# SC32F10T_10G register map
File version: 1.0
CPU: CM0+ r0p1, little endian, MPU, no FPU, 4 interrupt priority bits
Registers are 32-bit, read-write, reset 0x0 unless marked. A register's access mark holds for its fields unless they carry their own. Offsets are from the block's base; [hi:lo] are bit positions; 'fields as' and 'values as' point back to an identical list.

## UART0
Base 0x40020020
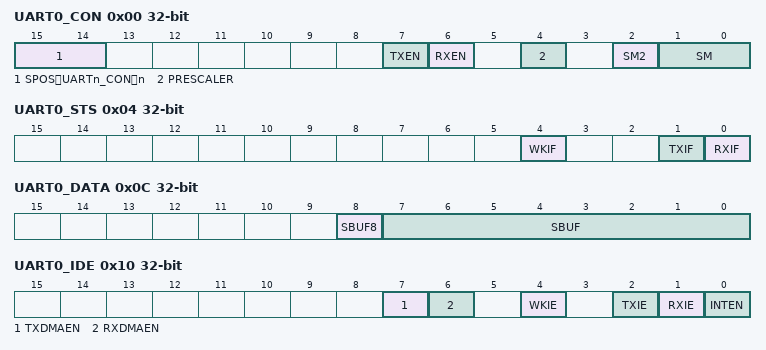
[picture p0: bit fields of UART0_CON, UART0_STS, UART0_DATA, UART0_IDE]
0x00 UART0_CON — UART控制寄存器
  [15:14] SPOS（UARTn_CON，n — 此bit位，仅在UARTn_CON，n=2的情况下有效：UART2信号口映射控制位@UART2_CON信号SPOS值RX2TX2SPOS[1:0]=00PB0PA15SPOS[1:0]=01PA11PA10
  [7] TXEN — UART发送允许控制位0：不允许发送数据，TXD信号不再影响所在管脚的状态。此时若用户程序限制发送功能，仅用到了接收，那么与TX脚复用的其它功能将不受影响1：允许发送数据，TXD所在管脚切换为TXD信号口模式
  [6] RXEN — UART接收允许控制位0：不允许接收数据1：允许接收数据
  [4] PRESCALER — 波特率倍率设置位该位在UART的不同模式下有不同定义：当SM0~1 = 01（UART模式1）或SM0~1 = 11（UART模式3）：0: 串行端口在系统时钟的1分频下运行1: 串行端口在系统时钟的16分频下运行当SM0~1 = 00（UART模式0）波特率倍率设置位：0：串行端口在系统时钟的12分频下运行1：串行端口在系统时钟的4分频下运行
  [2] SM2 — RB8置位中断允许位该位仅在模式3有效0：每收到一个完整的数据帧就置位RI产生中断请求；1：收到一个完整的数据帧时，只有当RB8=1时才会置位RI产生中断请求
  [1:0] SM — UART通信模式控制位00：模式0，8位半双工同步通信模式，在RX引脚上收发串行数据。TX 引脚用作发送移位时钟。每帧收发8位，低位先接收或发送。在该模式下使能RXEN位，UART将发出一个完整一帧的时钟，并且将RXIF置1；01：模式1，10位全双工异步通信，由1个起始位，8个数据位和1个停止位组成，通信波特率可变；10：保留11：模式3，11位全双工异步通信，由1个起始位，8个数据位，一个可编
0x04 UART0_STS — UART标志位寄存器
  [4] WKIF — UART唤醒标志位UART从STOP模式唤醒后，该位由硬件置1，如果此时WKIE = 1，将产生中断。该位由软件写1清0。
  [1] TXIF — 发送中断标志位数据发送完成该位由硬件置1，如果此时TXIE = 1，将产生中断。该位由软件写1清0。注意：在DMA模式下，DMA写入发送缓存后，该位由DMA模块清0，此时用户无需通过软件清0。
  [0] RXIF — 接收中断标志位数据接收完成该位由硬件置1，如果此时RXIE = 1，将产生中断。该位由软件写1清0。注意：在DMA模式下，DMA读取接收缓存后，该位由DMA模块清0，此时用户无需通过软件清0。
0x08 UART0_BAUD — UART波特率寄存器
  [15:0] BAUD — UART波特率配置位写入BAUD[15:0]后，UART的波特率将按照以下公式配置：BaudRate=fUART / BAUD[15:0]其中fUART为UART时钟源经预分频之后的最终频率，见PRESCALER位说明。
0x0C UART0_DATA — UART数据寄存器
  [8] SBUF8 — UART的发送/接收数据的第9位该位仅在模式3有效。
  [7:0] SBUF — UART数据缓存读操作：将返回接收锁存器中的内容写操作：SBUF的数据将送至发送移位寄存器，并启动发送流程
0x10 UART0_IDE — 通信口DMA控制寄存器
  [7] TXDMAEN — DMA发送通道使能位0：禁用DMA发送功能1：使能DMA发送功能该位使能后，TXIF置起可触发DMA通道发送请求注意：UART0和UART1可产生DMA请求UART2和UART3不能产生DMA请求
  [6] RXDMAEN — DMA接收通道使能位0：禁用DMA接收功能1：使能DMA接收功能该位使能后，RXIF置起可触发DMA通道接收请求注意：UART0和UART1可产生DMA请求UART2和UART3不能产生DMA请求
  [4] WKIE — UART唤醒中断使能位0：WKIF置起时，不允许产生中断1：WKIF置起时，产生中断
  [2] TXIE — UART发送中断使能位0：TXIF置起时，不允许产生中断1：TXIF置起时，产生中断
  [1] RXIE — UART接收中断使能位0：RXIF置起时，不允许产生中断1：RXIF置起时，产生中断
  [0] INTEN — 中断请求 CPU的使能控制位0：禁止中断请求1：使能中断请求

## UART1
Base 0x40020080
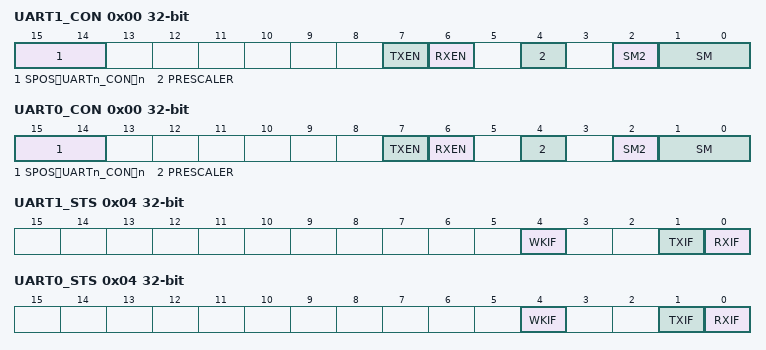
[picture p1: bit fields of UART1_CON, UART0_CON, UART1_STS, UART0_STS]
0x00 UART1_CON — UART控制寄存器
  [15:14] SPOS（UARTn_CON，n — 此bit位，仅在UARTn_CON，n=2的情况下有效：UART2信号口映射控制位@UART2_CON信号SPOS值RX2TX2SPOS[1:0]=00PB0PA15SPOS[1:0]=01PA11PA10
  [7] TXEN — UART发送允许控制位0：不允许发送数据，TXD信号不再影响所在管脚的状态。此时若用户程序限制发送功能，仅用到了接收，那么与TX脚复用的其它功能将不受影响1：允许发送数据，TXD所在管脚切换为TXD信号口模式
  [6] RXEN — UART接收允许控制位0：不允许接收数据1：允许接收数据
  [4] PRESCALER — 波特率倍率设置位该位在UART的不同模式下有不同定义：当SM0~1 = 01（UART模式1）或SM0~1 = 11（UART模式3）：0: 串行端口在系统时钟的1分频下运行1: 串行端口在系统时钟的16分频下运行当SM0~1 = 00（UART模式0）波特率倍率设置位：0：串行端口在系统时钟的12分频下运行1：串行端口在系统时钟的4分频下运行
  [2] SM2 — RB8置位中断允许位该位仅在模式3有效0：每收到一个完整的数据帧就置位RI产生中断请求；1：收到一个完整的数据帧时，只有当RB8=1时才会置位RI产生中断请求
  [1:0] SM — UART通信模式控制位00：模式0，8位半双工同步通信模式，在RX引脚上收发串行数据。TX 引脚用作发送移位时钟。每帧收发8位，低位先接收或发送。在该模式下使能RXEN位，UART将发出一个完整一帧的时钟，并且将RXIF置1；01：模式1，10位全双工异步通信，由1个起始位，8个数据位和1个停止位组成，通信波特率可变；10：保留11：模式3，11位全双工异步通信，由1个起始位，8个数据位，一个可编
0x00 UART0_CON — UART控制寄存器
  fields as UART1_CON
0x04 UART1_STS — UART标志位寄存器
  [4] WKIF — UART唤醒标志位UART从STOP模式唤醒后，该位由硬件置1，如果此时WKIE = 1，将产生中断。该位由软件写1清0。
  [1] TXIF — 发送中断标志位数据发送完成该位由硬件置1，如果此时TXIE = 1，将产生中断。该位由软件写1清0。注意：在DMA模式下，DMA写入发送缓存后，该位由DMA模块清0，此时用户无需通过软件清0。
  [0] RXIF — 接收中断标志位数据接收完成该位由硬件置1，如果此时RXIE = 1，将产生中断。该位由软件写1清0。注意：在DMA模式下，DMA读取接收缓存后，该位由DMA模块清0，此时用户无需通过软件清0。
0x04 UART0_STS — UART标志位寄存器
  fields as UART1_STS
0x08 UART1_BAUD — UART波特率寄存器
  [15:0] BAUD — UART波特率配置位写入BAUD[15:0]后，UART的波特率将按照以下公式配置：BaudRate=fUART / BAUD[15:0]其中fUART为UART时钟源经预分频之后的最终频率，见PRESCALER位说明。
0x08 UART0_BAUD — UART波特率寄存器
  fields as UART1_BAUD
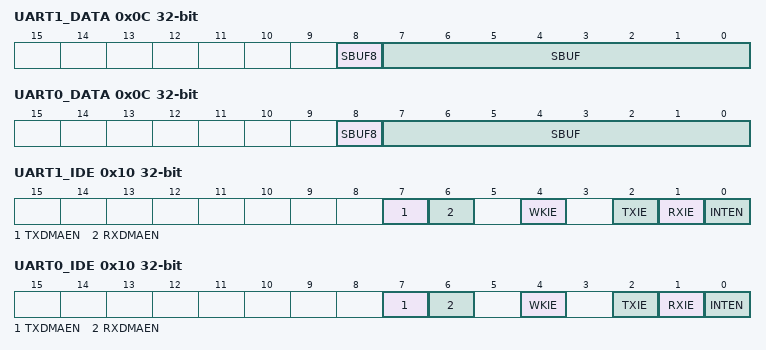
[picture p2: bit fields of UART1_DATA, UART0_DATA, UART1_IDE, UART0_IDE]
0x0C UART1_DATA — UART数据寄存器
  [8] SBUF8 — UART的发送/接收数据的第9位该位仅在模式3有效。
  [7:0] SBUF — UART数据缓存读操作：将返回接收锁存器中的内容写操作：SBUF的数据将送至发送移位寄存器，并启动发送流程
0x0C UART0_DATA — UART数据寄存器
  fields as UART1_DATA
0x10 UART1_IDE — 通信口DMA控制寄存器
  [7] TXDMAEN — DMA发送通道使能位0：禁用DMA发送功能1：使能DMA发送功能该位使能后，TXIF置起可触发DMA通道发送请求注意：UART0和UART1可产生DMA请求UART2和UART3不能产生DMA请求
  [6] RXDMAEN — DMA接收通道使能位0：禁用DMA接收功能1：使能DMA接收功能该位使能后，RXIF置起可触发DMA通道接收请求注意：UART0和UART1可产生DMA请求UART2和UART3不能产生DMA请求
  [4] WKIE — UART唤醒中断使能位0：WKIF置起时，不允许产生中断1：WKIF置起时，产生中断
  [2] TXIE — UART发送中断使能位0：TXIF置起时，不允许产生中断1：TXIF置起时，产生中断
  [1] RXIE — UART接收中断使能位0：RXIF置起时，不允许产生中断1：RXIF置起时，产生中断
  [0] INTEN — 中断请求 CPU的使能控制位0：禁止中断请求1：使能中断请求
0x10 UART0_IDE — 通信口DMA控制寄存器
  fields as UART1_IDE

## UART3
Base 0x40022020
Registers as UART1 (with UART1 read as UART3); these are added or differ:
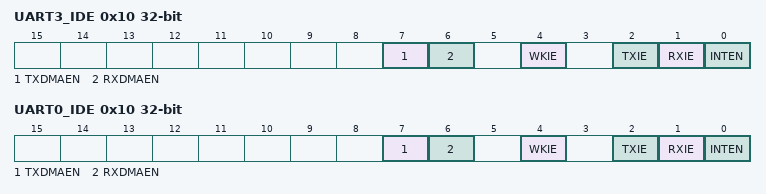
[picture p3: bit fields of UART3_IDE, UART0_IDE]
0x10 UART3_IDE — 通信口DMA控制寄存器
  fields as UART1.UART1_IDE
0x10 UART0_IDE — 通信口DMA控制寄存器
  fields as UART1.UART1_IDE
